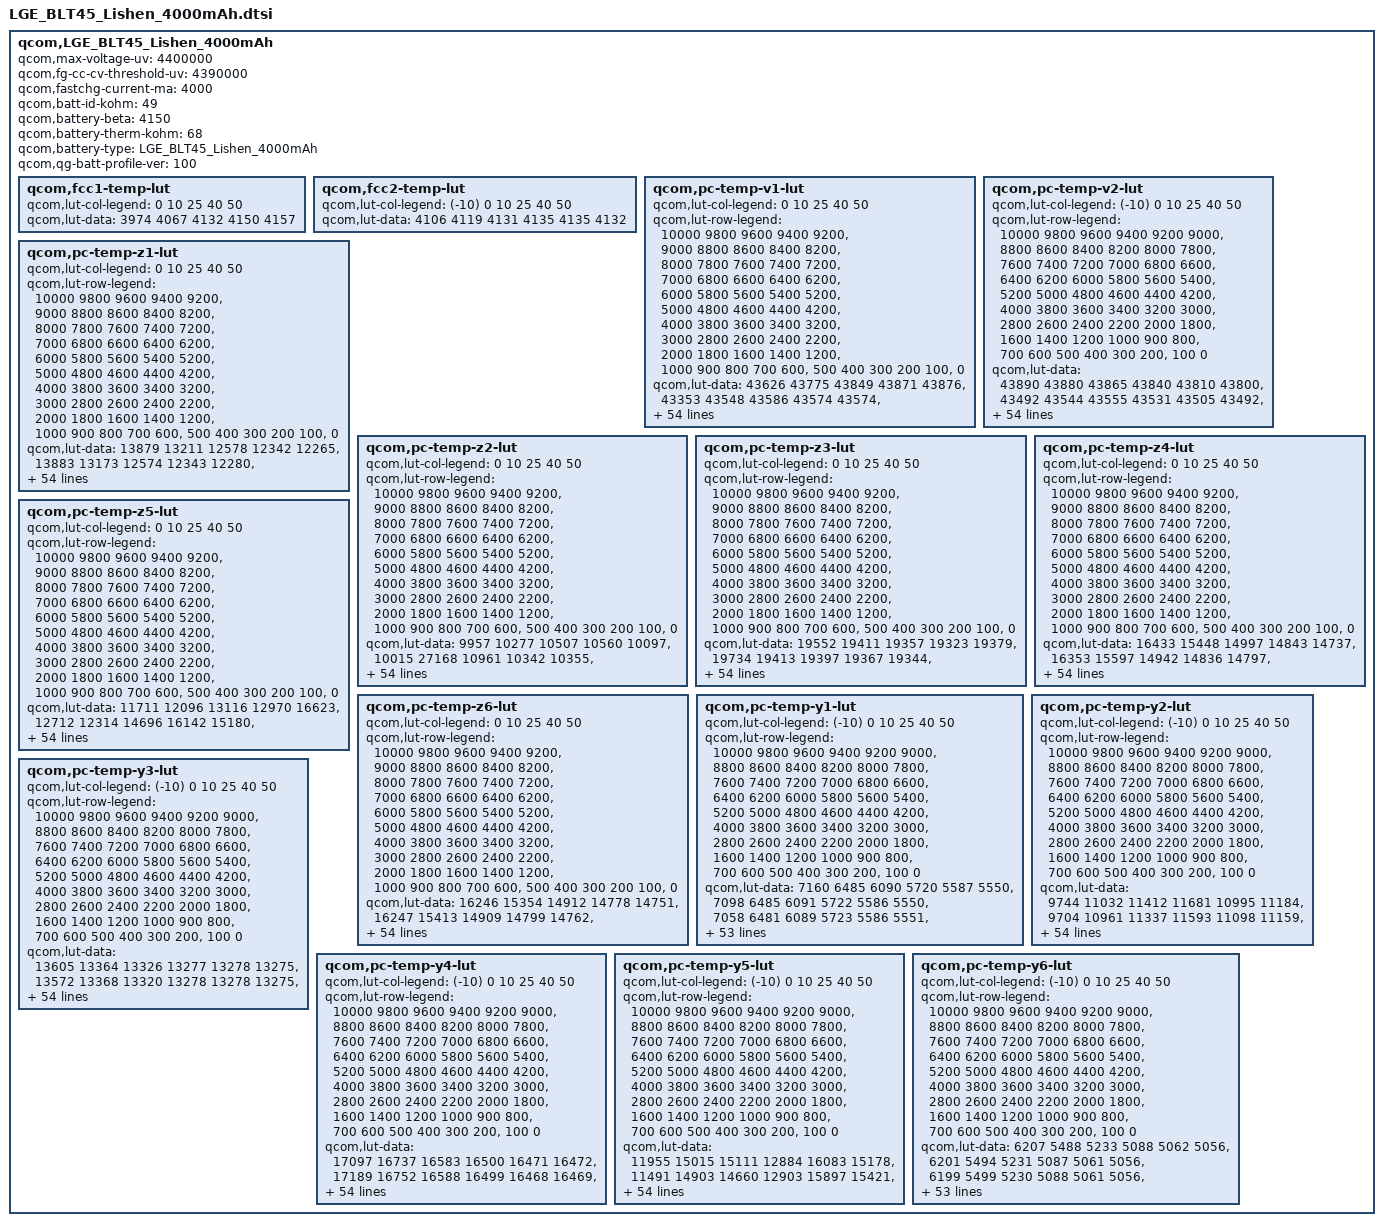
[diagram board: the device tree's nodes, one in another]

qcom,LGE_BLT45_Lishen_4000mAh {
    /* 3888979_LGE_BLT45_4000mAh_averaged_MasterSlave_Mar6th2019 */
    qcom,max-voltage-uv = <4400000>;
    qcom,fg-cc-cv-threshold-uv = <4390000>;
    qcom,fastchg-current-ma = <4000>;
    qcom,batt-id-kohm = <49>;
    qcom,battery-beta = <4150>;
    qcom,battery-therm-kohm = <68>;
    qcom,battery-type = "LGE_BLT45_Lishen_4000mAh";
    qcom,qg-batt-profile-ver = <100>;

	qcom,fcc1-temp-lut {
		qcom,lut-col-legend = <0 10 25 40 50>;
		qcom,lut-data = <3974 4067 4132 4150 4157>;
	};

	qcom,fcc2-temp-lut {
		qcom,lut-col-legend = <(-10) 0 10 25 40 50>;
		qcom,lut-data = <4106 4119 4131 4135 4135 4132>;
	};

	qcom,pc-temp-v1-lut {
		qcom,lut-col-legend = <0 10 25 40 50>;
		qcom,lut-row-legend = <10000 9800 9600 9400 9200>,
			<9000 8800 8600 8400 8200>,
			<8000 7800 7600 7400 7200>,
			<7000 6800 6600 6400 6200>,
			<6000 5800 5600 5400 5200>,
			<5000 4800 4600 4400 4200>,
			<4000 3800 3600 3400 3200>,
			<3000 2800 2600 2400 2200>,
			<2000 1800 1600 1400 1200>,
			<1000 900 800 700 600>,
			<500 400 300 200 100>,
			<0>;
		qcom,lut-data = <43626 43775 43849 43871 43876>,
			<43353 43548 43586 43574 43574>,
			<43091 43292 43343 43330 43326>,
			<42841 43026 43101 43094 43092>,
			<42601 42777 42859 42860 42861>,
			<42365 42536 42615 42623 42626>,
			<42134 42299 42372 42385 42390>,
			<41907 42064 42135 42151 42158>,
			<41684 41834 41903 41924 41930>,
			<41466 41609 41676 41698 41706>,
			<41255 41390 41453 41471 41481>,
			<41052 41182 41236 41248 41260>,
			<40854 40991 41024 41035 41044>,
			<40654 40801 40821 40832 40835>,
			<40453 40598 40622 40634 40633>,
			<40267 40393 40427 40441 40442>,
			<40097 40205 40242 40255 40259>,
			<39937 40034 40071 40080 40084>,
			<39784 39872 39911 39914 39916>,
			<39639 39725 39759 39756 39756>,
			<39497 39583 39621 39615 39613>,
			<39355 39418 39460 39460 39459>,
			<39216 39228 39211 39239 39245>,
			<39076 39037 38948 38992 39001>,
			<38935 38840 38798 38823 38829>,
			<38798 38662 38699 38705 38708>,
			<38652 38556 38606 38602 38602>,
			<38519 38487 38509 38504 38502>,
			<38427 38425 38419 38415 38410>,
			<38356 38364 38341 38332 38327>,
			<38304 38309 38271 38255 38252>,
			<38266 38257 38208 38187 38182>,
			<38236 38209 38152 38128 38117>,
			<38209 38166 38102 38074 38056>,
			<38186 38130 38063 38026 38001>,
			<38162 38097 38027 37980 37948>,
			<38138 38067 37990 37931 37890>,
			<38109 38040 37952 37878 37831>,
			<38064 37999 37904 37815 37761>,
			<37990 37920 37827 37736 37674>,
			<37899 37819 37728 37641 37572>,
			<37783 37708 37621 37535 37463>,
			<37649 37577 37497 37412 37340>,
			<37508 37420 37344 37264 37187>,
			<37349 37264 37193 37116 37042>,
			<37215 37147 37086 37017 36956>,
			<37170 37110 37055 36986 36927>,
			<37133 37083 37032 36963 36903>,
			<37102 37058 37010 36942 36884>,
			<37060 37022 36974 36899 36831>,
			<36911 36850 36785 36678 36587>,
			<36495 36435 36372 36256 36159>,
			<35923 35858 35803 35689 35592>,
			<35134 35059 35028 34915 34816>,
			<33861 33762 33827 33720 33617>,
			<30000 30000 30000 30000 30000>;
	};

	qcom,pc-temp-v2-lut {
		qcom,lut-col-legend = <(-10) 0 10 25 40 50>;
		qcom,lut-row-legend = <10000 9800 9600 9400 9200 9000>,
			<8800 8600 8400 8200 8000 7800>,
			<7600 7400 7200 7000 6800 6600>,
			<6400 6200 6000 5800 5600 5400>,
			<5200 5000 4800 4600 4400 4200>,
			<4000 3800 3600 3400 3200 3000>,
			<2800 2600 2400 2200 2000 1800>,
			<1600 1400 1200 1000 900 800>,
			<700 600 500 400 300 200>,
			<100 0>;
		qcom,lut-data = <43890 43880 43865 43840 43810 43800>,
			<43492 43544 43555 43531 43505 43492>,
			<43139 43236 43266 43243 43222 43207>,
			<42834 42961 43003 42981 42962 42948>,
			<42570 42715 42761 42741 42724 42712>,
			<42329 42474 42523 42504 42489 42479>,
			<42112 42232 42284 42265 42252 42244>,
			<41904 41995 42048 42029 42017 42010>,
			<41674 41765 41819 41798 41786 41780>,
			<41430 41542 41593 41571 41558 41553>,
			<41206 41323 41370 41347 41335 41330>,
			<41011 41110 41149 41127 41116 41111>,
			<40812 40900 40932 40912 40902 40897>,
			<40581 40697 40726 40706 40696 40692>,
			<40325 40496 40525 40506 40496 40491>,
			<40060 40282 40328 40312 40304 40300>,
			<39771 40054 40137 40122 40121 40116>,
			<39510 39830 39945 39944 39946 39941>,
			<39307 39616 39753 39786 39784 39778>,
			<39128 39410 39558 39630 39625 39619>,
			<38954 39216 39350 39441 39453 39448>,
			<38785 39029 39133 39224 39271 39271>,
			<38631 38862 38943 39020 39080 39084>,
			<38487 38715 38782 38827 38865 38870>,
			<38361 38580 38641 38658 38672 38676>,
			<38262 38452 38514 38531 38541 38544>,
			<38181 38332 38400 38425 38438 38439>,
			<38113 38226 38298 38328 38341 38341>,
			<38056 38133 38206 38238 38251 38250>,
			<38004 38051 38122 38158 38169 38166>,
			<37955 37982 38045 38087 38096 38090>,
			<37907 37923 37973 38021 38027 38019>,
			<37858 37873 37908 37960 37967 37958>,
			<37805 37833 37849 37902 37913 37904>,
			<37751 37792 37796 37844 37853 37841>,
			<37693 37745 37752 37786 37774 37749>,
			<37630 37695 37708 37724 37686 37646>,
			<37562 37639 37657 37651 37596 37545>,
			<37489 37575 37598 37569 37501 37443>,
			<37411 37503 37530 37490 37415 37352>,
			<37325 37416 37452 37418 37344 37279>,
			<37231 37316 37355 37331 37257 37192>,
			<37127 37202 37232 37220 37145 37080>,
			<37024 37064 37100 37099 37025 36961>,
			<36931 36926 36938 36950 36880 36819>,
			<36826 36819 36863 36889 36831 36776>,
			<36775 36778 36831 36873 36817 36760>,
			<36719 36738 36807 36852 36797 36747>,
			<36654 36688 36768 36830 36773 36719>,
			<36561 36611 36704 36779 36708 36638>,
			<36401 36443 36496 36594 36458 36343>,
			<36110 36038 35997 36128 35972 35853>,
			<35604 35423 35306 35510 35334 35205>,
			<34786 34552 34347 34646 34444 34303>,
			<33329 33070 32940 33367 33131 32954>,
			<30767 29268 27853 27944 27987 27971>;
	};

	qcom,pc-temp-z1-lut {
		qcom,lut-col-legend = <0 10 25 40 50>;
		qcom,lut-row-legend = <10000 9800 9600 9400 9200>,
			<9000 8800 8600 8400 8200>,
			<8000 7800 7600 7400 7200>,
			<7000 6800 6600 6400 6200>,
			<6000 5800 5600 5400 5200>,
			<5000 4800 4600 4400 4200>,
			<4000 3800 3600 3400 3200>,
			<3000 2800 2600 2400 2200>,
			<2000 1800 1600 1400 1200>,
			<1000 900 800 700 600>,
			<500 400 300 200 100>,
			<0>;
		qcom,lut-data = <13879 13211 12578 12342 12265>,
			<13883 13173 12574 12343 12280>,
			<13886 13166 12570 12336 12280>,
			<13888 13163 12564 12335 12281>,
			<13887 13164 12559 12334 12281>,
			<13882 13166 12555 12335 12283>,
			<13871 13166 12552 12336 12286>,
			<13859 13153 12552 12337 12288>,
			<13852 13137 12553 12337 12289>,
			<13845 13134 12553 12338 12290>,
			<13839 13132 12552 12338 12291>,
			<13828 13132 12551 12338 12291>,
			<13814 13136 12552 12338 12292>,
			<13803 13140 12552 12338 12293>,
			<13792 13136 12553 12339 12294>,
			<13789 13127 12552 12340 12295>,
			<13798 13126 12551 12341 12296>,
			<13808 13134 12552 12342 12297>,
			<13808 13140 12555 12344 12298>,
			<13806 13141 12559 12346 12300>,
			<13806 13141 12562 12347 12302>,
			<13818 13144 12566 12349 12304>,
			<13830 13153 12571 12351 12307>,
			<13833 13160 12576 12355 12310>,
			<13834 13165 12581 12360 12314>,
			<13836 13171 12587 12365 12318>,
			<13841 13176 12594 12369 12321>,
			<13847 13183 12600 12372 12324>,
			<13855 13189 12606 12376 12327>,
			<13867 13195 12610 12378 12330>,
			<13877 13200 12613 12381 12332>,
			<13884 13206 12617 12383 12334>,
			<13890 13216 12620 12387 12336>,
			<13896 13220 12623 12390 12338>,
			<13901 13215 12626 12393 12341>,
			<13906 13212 12629 12396 12344>,
			<13915 13217 12633 12399 12347>,
			<13925 13230 12637 12401 12350>,
			<13929 13237 12641 12404 12352>,
			<13930 13247 12645 12407 12355>,
			<13934 13255 12650 12411 12357>,
			<13955 13257 12654 12414 12360>,
			<13971 13260 12658 12416 12363>,
			<13952 13273 12662 12420 12366>,
			<13966 13277 12667 12423 12368>,
			<13959 13280 12678 12425 12369>,
			<13941 13273 12675 12426 12370>,
			<13969 13277 12674 12427 12371>,
			<13937 13272 12676 12428 12372>,
			<13943 13287 12684 12432 12376>,
			<13967 13298 12697 12439 12381>,
			<14000 13305 12703 12448 12391>,
			<13988 13333 12724 12463 12404>,
			<14030 13365 12752 12484 12422>,
			<14030 13365 12752 12484 12422>,
			<14030 13365 12752 12484 12422>;
	};

	qcom,pc-temp-z2-lut {
		qcom,lut-col-legend = <0 10 25 40 50>;
		qcom,lut-row-legend = <10000 9800 9600 9400 9200>,
			<9000 8800 8600 8400 8200>,
			<8000 7800 7600 7400 7200>,
			<7000 6800 6600 6400 6200>,
			<6000 5800 5600 5400 5200>,
			<5000 4800 4600 4400 4200>,
			<4000 3800 3600 3400 3200>,
			<3000 2800 2600 2400 2200>,
			<2000 1800 1600 1400 1200>,
			<1000 900 800 700 600>,
			<500 400 300 200 100>,
			<0>;
		qcom,lut-data = <9957 10277 10507 10560 10097>,
			<10015 27168 10961 10342 10355>,
			<10048 19545 11415 10492 10292>,
			<10050 10977 11205 10868 10307>,
			<10050 10253 10941 11244 10315>,
			<10050 10234 10696 11092 10344>,
			<10049 10218 10479 10616 10408>,
			<10047 10202 10484 10481 10424>,
			<10043 10192 10683 10767 10330>,
			<10035 10196 10799 11001 10246>,
			<10025 10215 10786 10829 10247>,
			<10012 10253 10767 10522 10254>,
			<10002 10384 10772 10509 10262>,
			<10000 10501 10786 10755 10275>,
			<10000 10535 10792 10915 10286>,
			<10004 10557 10784 10946 10291>,
			<10103 10550 10763 10962 10296>,
			<10213 10462 10696 10851 10312>,
			<10197 10397 10595 10520 10346>,
			<10120 10414 10574 10405 10371>,
			<10085 10449 10590 10418 10385>,
			<10104 10467 10601 10439 10397>,
			<10135 10478 10590 10501 10414>,
			<10163 10483 10575 10589 10432>,
			<10192 10482 10581 10612 10442>,
			<10218 10478 10611 10609 10443>,
			<10240 10471 10625 10599 10433>,
			<10259 10455 10602 10526 10379>,
			<10277 10447 10572 10442 10305>,
			<10294 10450 10555 10431 10265>,
			<10308 10456 10542 10429 10236>,
			<10319 10466 10541 10425 10228>,
			<10329 10487 10556 10392 10249>,
			<10343 10509 10579 10363 10282>,
			<10361 10530 10606 10374 10315>,
			<10381 10552 10638 10406 10354>,
			<10407 10573 10661 10446 10403>,
			<10435 10592 10677 10511 10471>,
			<10462 10611 10697 10572 10521>,
			<10489 10630 10735 10631 10546>,
			<10513 10647 10775 10678 10562>,
			<10540 10656 10791 10681 10561>,
			<10553 10664 10800 10668 10550>,
			<10198 10684 10807 10656 10548>,
			<13003 10791 10834 10649 10543>,
			<13477 10961 10885 10685 10524>,
			<15126 11039 10899 10689 10537>,
			<19313 11519 10911 10688 10547>,
			<15753 12078 10894 10702 10644>,
			<19263 12169 10929 10870 10698>,
			<16093 11828 11098 10668 10446>,
			<16101 11528 11055 10502 10289>,
			<10893 11351 10911 10437 10220>,
			<10142 10879 10911 10351 10124>,
			<10142 10879 10911 10351 10124>,
			<10142 10879 10911 10351 10124>;
	};

	qcom,pc-temp-z3-lut {
		qcom,lut-col-legend = <0 10 25 40 50>;
		qcom,lut-row-legend = <10000 9800 9600 9400 9200>,
			<9000 8800 8600 8400 8200>,
			<8000 7800 7600 7400 7200>,
			<7000 6800 6600 6400 6200>,
			<6000 5800 5600 5400 5200>,
			<5000 4800 4600 4400 4200>,
			<4000 3800 3600 3400 3200>,
			<3000 2800 2600 2400 2200>,
			<2000 1800 1600 1400 1200>,
			<1000 900 800 700 600>,
			<500 400 300 200 100>,
			<0>;
		qcom,lut-data = <19552 19411 19357 19323 19379>,
			<19734 19413 19397 19367 19344>,
			<19841 19509 19427 19394 19375>,
			<19850 19619 19451 19409 19382>,
			<19853 19631 19467 19417 19386>,
			<19853 19632 19466 19418 19392>,
			<19838 19633 19465 19415 19399>,
			<19819 19631 19466 19414 19401>,
			<19808 19627 19473 19413 19391>,
			<19799 19614 19475 19411 19380>,
			<19791 19589 19464 19405 19378>,
			<19784 19583 19453 19394 19377>,
			<19778 19610 19451 19391 19375>,
			<19766 19633 19451 19389 19374>,
			<19748 19621 19450 19387 19372>,
			<19741 19591 19440 19385 19367>,
			<19756 19567 19427 19382 19361>,
			<19773 19545 19418 19378 19358>,
			<19754 19531 19409 19370 19357>,
			<19693 19524 19405 19365 19354>,
			<19666 19520 19402 19361 19350>,
			<19675 19523 19401 19359 19347>,
			<19688 19549 19415 19361 19348>,
			<19700 19568 19434 19365 19353>,
			<19711 19572 19433 19375 19361>,
			<19721 19574 19419 19396 19383>,
			<19729 19573 19413 19408 19395>,
			<19734 19566 19426 19406 19394>,
			<19733 19559 19440 19403 19391>,
			<19726 19553 19440 19400 19386>,
			<19718 19548 19436 19398 19378>,
			<19709 19548 19434 19394 19371>,
			<19698 19547 19432 19385 19367>,
			<19687 19547 19430 19376 19363>,
			<19676 19544 19426 19370 19358>,
			<19666 19540 19422 19364 19352>,
			<19657 19535 19418 19363 19348>,
			<19649 19529 19415 19362 19344>,
			<19641 19524 19413 19362 19343>,
			<19634 19520 19412 19362 19346>,
			<19625 19516 19410 19361 19352>,
			<19613 19510 19408 19359 19352>,
			<19591 19503 19404 19356 19350>,
			<19339 19494 19401 19356 19356>,
			<19258 19468 19395 19357 19362>,
			<19257 19438 19384 19347 19346>,
			<19257 19423 19377 19342 19339>,
			<19256 19333 19366 19340 19335>,
			<19257 19288 19366 19337 19321>,
			<19256 19280 19361 19321 19320>,
			<19257 19311 19350 19348 19349>,
			<19257 19309 19348 19358 19356>,
			<19259 19308 19363 19359 19358>,
			<19261 19328 19349 19363 19362>,
			<19261 19328 19349 19363 19362>,
			<19261 19328 19349 19363 19362>;
	};

	qcom,pc-temp-z4-lut {
		qcom,lut-col-legend = <0 10 25 40 50>;
		qcom,lut-row-legend = <10000 9800 9600 9400 9200>,
			<9000 8800 8600 8400 8200>,
			<8000 7800 7600 7400 7200>,
			<7000 6800 6600 6400 6200>,
			<6000 5800 5600 5400 5200>,
			<5000 4800 4600 4400 4200>,
			<4000 3800 3600 3400 3200>,
			<3000 2800 2600 2400 2200>,
			<2000 1800 1600 1400 1200>,
			<1000 900 800 700 600>,
			<500 400 300 200 100>,
			<0>;
		qcom,lut-data = <16433 15448 14997 14843 14737>,
			<16353 15597 14942 14836 14797>,
			<16232 15478 15015 14884 14848>,
			<16052 15298 14945 14849 14835>,
			<15810 15181 14874 14804 14811>,
			<15624 15085 14844 14786 14787>,
			<15494 15011 14821 14772 14762>,
			<15388 14954 14792 14760 14750>,
			<15301 14910 14750 14736 14746>,
			<15227 14882 14727 14718 14742>,
			<15164 14861 14725 14719 14736>,
			<15107 14829 14723 14724 14730>,
			<15059 14760 14716 14722 14723>,
			<15026 14710 14703 14707 14717>,
			<15001 14720 14699 14696 14711>,
			<14966 14745 14702 14690 14706>,
			<14892 14761 14706 14685 14701>,
			<14830 14772 14709 14684 14696>,
			<14839 14777 14711 14688 14689>,
			<14880 14771 14709 14688 14684>,
			<14898 14762 14705 14684 14680>,
			<14875 14761 14702 14682 14677>,
			<14848 14775 14766 14732 14721>,
			<14843 14796 14856 14825 14809>,
			<14841 14842 14864 14836 14824>,
			<14840 14893 14845 14794 14782>,
			<14868 14895 14821 14758 14746>,
			<14902 14868 14788 14741 14732>,
			<14907 14843 14757 14728 14722>,
			<14908 14825 14742 14717 14715>,
			<14907 14810 14732 14708 14709>,
			<14897 14796 14725 14702 14703>,
			<14880 14784 14719 14699 14695>,
			<14866 14775 14715 14696 14689>,
			<14853 14770 14711 14693 14686>,
			<14839 14766 14708 14691 14684>,
			<14823 14759 14707 14691 14684>,
			<14808 14752 14706 14694 14689>,
			<14795 14748 14706 14697 14695>,
			<14783 14746 14711 14704 14700>,
			<14775 14744 14717 14711 14704>,
			<14772 14736 14713 14709 14702>,
			<14771 14722 14701 14702 14696>,
			<15007 14715 14699 14704 14697>,
			<15030 14704 14694 14702 14695>,
			<14981 14690 14673 14685 14677>,
			<14975 14698 14670 14681 14674>,
			<14971 14794 14667 14666 14660>,
			<14961 14837 14654 14647 14650>,
			<14957 14838 14655 14654 14641>,
			<14956 14810 14684 14660 14655>,
			<14978 14824 14695 14661 14661>,
			<14994 14834 14681 14664 14662>,
			<15027 14831 14702 14662 14660>,
			<15027 14831 14702 14662 14660>,
			<15027 14831 14702 14662 14660>;
	};

	qcom,pc-temp-z5-lut {
		qcom,lut-col-legend = <0 10 25 40 50>;
		qcom,lut-row-legend = <10000 9800 9600 9400 9200>,
			<9000 8800 8600 8400 8200>,
			<8000 7800 7600 7400 7200>,
			<7000 6800 6600 6400 6200>,
			<6000 5800 5600 5400 5200>,
			<5000 4800 4600 4400 4200>,
			<4000 3800 3600 3400 3200>,
			<3000 2800 2600 2400 2200>,
			<2000 1800 1600 1400 1200>,
			<1000 900 800 700 600>,
			<500 400 300 200 100>,
			<0>;
		qcom,lut-data = <11711 12096 13116 12970 16623>,
			<12712 12314 14696 16142 15180>,
			<13418 13544 15534 17498 17535>,
			<13758 15208 16473 18666 18276>,
			<13977 15909 17447 19535 18815>,
			<14160 16337 18048 20157 20007>,
			<14312 16819 18615 20633 21808>,
			<14458 17550 19823 21006 22336>,
			<14632 18075 22310 21827 21219>,
			<14829 18098 23535 22421 20226>,
			<15052 18077 22788 22076 20390>,
			<15369 18204 21896 21425 20878>,
			<15659 19728 22328 21313 21407>,
			<15802 21169 23839 21612 22136>,
			<15958 21274 24297 22184 22495>,
			<16276 21057 22748 22898 22161>,
			<18075 20737 21105 23455 21722>,
			<19912 20173 20574 23330 21969>,
			<19496 19818 20327 22562 22967>,
			<17730 20071 20439 22423 23539>,
			<16971 20833 20694 22674 23746>,
			<18385 23407 21134 22815 23844>,
			<20892 32414 24251 21852 22367>,
			<23706 37886 28261 20075 19354>,
			<27352 36562 27146 19725 18698>,
			<30815 33939 20920 19858 19144>,
			<34518 31284 18099 20066 19755>,
			<37272 28099 19517 20590 20809>,
			<37227 26435 21465 21445 21842>,
			<35797 26045 22527 22688 21909>,
			<34198 25842 23342 24418 21732>,
			<32556 26367 24453 24962 21701>,
			<30933 28403 26191 24319 22611>,
			<29685 30238 27742 23737 23716>,
			<28567 31830 28727 23950 24280>,
			<28093 32886 29464 24567 24688>,
			<28184 32830 29796 25295 24665>,
			<28389 32505 30003 26355 23966>,
			<28639 32361 30076 26907 23503>,
			<29086 32364 29776 26007 23745>,
			<29312 32360 29242 24392 24087>,
			<27828 31918 28742 23074 23737>,
			<24508 30764 28167 21928 22630>,
			<14110 28965 27373 21634 24201>,
			<11541 26042 26731 21790 26014>,
			<11647 23231 26442 20450 21917>,
			<11639 20371 24201 19401 19344>,
			<11618 13515 21497 19971 19875>,
			<11577 12107 22234 22393 18924>,
			<11580 11961 21443 18378 19961>,
			<11598 12749 17526 21035 23141>,
			<11563 12555 16291 20794 21800>,
			<11493 12422 17954 19516 19998>,
			<11398 12758 15562 19045 19304>,
			<11398 12758 15562 19045 19304>,
			<11398 12758 15562 19045 19304>;
	};

	qcom,pc-temp-z6-lut {
		qcom,lut-col-legend = <0 10 25 40 50>;
		qcom,lut-row-legend = <10000 9800 9600 9400 9200>,
			<9000 8800 8600 8400 8200>,
			<8000 7800 7600 7400 7200>,
			<7000 6800 6600 6400 6200>,
			<6000 5800 5600 5400 5200>,
			<5000 4800 4600 4400 4200>,
			<4000 3800 3600 3400 3200>,
			<3000 2800 2600 2400 2200>,
			<2000 1800 1600 1400 1200>,
			<1000 900 800 700 600>,
			<500 400 300 200 100>,
			<0>;
		qcom,lut-data = <16246 15354 14912 14778 14751>,
			<16247 15413 14909 14799 14762>,
			<16246 15393 14953 14832 14799>,
			<16196 15361 14933 14825 14796>,
			<16060 15326 14911 14814 14790>,
			<15949 15273 14897 14806 14785>,
			<15870 15229 14885 14799 14780>,
			<15804 15199 14872 14792 14774>,
			<15750 15173 14859 14782 14767>,
			<15705 15148 14848 14774 14760>,
			<15666 15125 14841 14770 14756>,
			<15631 15106 14835 14766 14752>,
			<15600 15089 14830 14762 14749>,
			<15571 15077 14825 14755 14745>,
			<15545 15072 14821 14750 14741>,
			<15523 15069 14817 14746 14736>,
			<15505 15064 14813 14743 14732>,
			<15490 15058 14809 14740 14727>,
			<15478 15052 14805 14737 14724>,
			<15469 15047 14802 14734 14720>,
			<15465 15042 14800 14730 14717>,
			<15463 15044 14799 14729 14714>,
			<15462 15063 14835 14753 14735>,
			<15464 15086 14885 14797 14776>,
			<15472 15113 14889 14805 14786>,
			<15483 15137 14875 14800 14781>,
			<15504 15137 14864 14793 14775>,
			<15523 15125 14858 14786 14769>,
			<15525 15113 14853 14779 14763>,
			<15524 15105 14847 14773 14757>,
			<15522 15098 14841 14768 14751>,
			<15516 15093 14837 14763 14745>,
			<15507 15089 14834 14757 14740>,
			<15499 15086 14831 14751 14735>,
			<15491 15083 14828 14747 14730>,
			<15485 15081 14825 14743 14725>,
			<15479 15078 14823 14742 14724>,
			<15474 15074 14822 14743 14725>,
			<15471 15073 14822 14744 14725>,
			<15469 15074 14824 14747 14729>,
			<15467 15075 14827 14750 14734>,
			<15465 15072 14825 14749 14734>,
			<15462 15066 14818 14745 14730>,
			<15450 15063 14817 14746 14734>,
			<15423 15052 14814 14746 14737>,
			<15411 15036 14801 14734 14721>,
			<15412 15034 14796 14729 14716>,
			<15412 15032 14790 14722 14709>,
			<15411 15031 14785 14713 14697>,
			<15416 15033 14784 14708 14692>,
			<15429 15045 14793 14725 14714>,
			<15454 15061 14801 14734 14724>,
			<15484 15078 14808 14738 14728>,
			<15533 15109 14818 14744 14734>,
			<15533 15109 14818 14744 14734>,
			<15533 15109 14818 14744 14734>;
	};

	qcom,pc-temp-y1-lut {
		qcom,lut-col-legend = <(-10) 0 10 25 40 50>;
		qcom,lut-row-legend = <10000 9800 9600 9400 9200 9000>,
			<8800 8600 8400 8200 8000 7800>,
			<7600 7400 7200 7000 6800 6600>,
			<6400 6200 6000 5800 5600 5400>,
			<5200 5000 4800 4600 4400 4200>,
			<4000 3800 3600 3400 3200 3000>,
			<2800 2600 2400 2200 2000 1800>,
			<1600 1400 1200 1000 900 800>,
			<700 600 500 400 300 200>,
			<100 0>;
		qcom,lut-data = <7160 6485 6090 5720 5587 5550>,
			<7098 6485 6091 5722 5586 5550>,
			<7058 6481 6089 5723 5586 5551>,
			<7035 6477 6087 5723 5585 5551>,
			<7025 6472 6085 5723 5584 5551>,
			<7024 6469 6083 5722 5584 5551>,
			<7044 6467 6082 5719 5584 5552>,
			<7067 6464 6080 5715 5584 5552>,
			<7065 6465 6078 5715 5584 5552>,
			<7050 6468 6076 5716 5585 5551>,
			<7039 6470 6075 5716 5584 5551>,
			<7030 6467 6075 5715 5583 5552>,
			<7025 6466 6076 5714 5582 5552>,
			<7029 6467 6076 5715 5582 5552>,
			<7040 6468 6077 5715 5583 5553>,
			<7046 6468 6078 5716 5584 5553>,
			<7050 6469 6078 5717 5587 5555>,
			<7052 6470 6078 5718 5588 5557>,
			<7051 6471 6076 5719 5589 5558>,
			<7047 6474 6074 5720 5589 5559>,
			<7047 6478 6074 5721 5590 5560>,
			<7060 6484 6076 5723 5591 5560>,
			<7066 6486 6078 5725 5592 5560>,
			<7053 6483 6080 5728 5594 5561>,
			<7036 6479 6081 5731 5595 5563>,
			<7039 6480 6084 5732 5596 5565>,
			<7056 6486 6088 5733 5598 5567>,
			<7064 6488 6090 5734 5599 5568>,
			<7073 6491 6091 5738 5601 5569>,
			<7082 6494 6093 5742 5603 5570>,
			<7074 6497 6096 5746 5605 5571>,
			<7054 6502 6099 5751 5607 5573>,
			<7047 6502 6100 5753 5609 5575>,
			<7047 6493 6101 5755 5612 5578>,
			<7046 6488 6101 5757 5614 5580>,
			<7041 6492 6102 5761 5616 5581>,
			<7033 6499 6104 5764 5618 5582>,
			<7032 6500 6105 5766 5620 5583>,
			<7035 6499 6105 5767 5621 5585>,
			<7037 6499 6105 5768 5622 5586>,
			<7036 6508 6105 5769 5625 5588>,
			<7036 6514 6106 5770 5626 5590>,
			<7038 6515 6115 5772 5627 5591>,
			<7041 6520 6113 5778 5628 5593>,
			<7051 6514 6121 5779 5631 5595>,
			<7074 6515 6130 5782 5633 5597>,
			<7072 6518 6125 5782 5635 5597>,
			<7068 6533 6123 5782 5634 5598>,
			<7085 6511 6130 5786 5635 5599>,
			<7083 6519 6126 5788 5636 5601>,
			<7113 6524 6134 5791 5638 5603>,
			<7118 6526 6143 5801 5644 5611>,
			<7159 6566 6161 5813 5657 5618>,
			<7298 6653 6197 5831 5670 5632>,
			<7298 6653 6197 5831 5670 5632>,
			<7298 6653 6197 5831 5670 5632>;
	};

	qcom,pc-temp-y2-lut {
		qcom,lut-col-legend = <(-10) 0 10 25 40 50>;
		qcom,lut-row-legend = <10000 9800 9600 9400 9200 9000>,
			<8800 8600 8400 8200 8000 7800>,
			<7600 7400 7200 7000 6800 6600>,
			<6400 6200 6000 5800 5600 5400>,
			<5200 5000 4800 4600 4400 4200>,
			<4000 3800 3600 3400 3200 3000>,
			<2800 2600 2400 2200 2000 1800>,
			<1600 1400 1200 1000 900 800>,
			<700 600 500 400 300 200>,
			<100 0>;
		qcom,lut-data = <9744 11032 11412 11681 10995 11184>,
			<9704 10961 11337 11593 11098 11159>,
			<9685 10891 11264 11504 11156 11134>,
			<9686 10827 11197 11420 11180 11109>,
			<9704 10771 11137 11351 11182 11084>,
			<9742 10731 11088 11302 11170 11058>,
			<10055 10696 11050 11273 11116 11027>,
			<10418 10675 11014 11246 11063 11002>,
			<10481 10674 10970 11198 11061 10992>,
			<10497 10677 10924 11133 11066 10986>,
			<10529 10681 10899 11096 11065 10982>,
			<10620 10696 10884 11076 11039 10967>,
			<10692 10721 10877 11064 11018 10953>,
			<10690 10769 10879 11068 11021 10948>,
			<10674 10832 10886 11084 11026 10942>,
			<10585 10848 10904 11087 11021 10933>,
			<10079 10844 10958 11085 10986 10917>,
			<9709 10843 11005 11088 10967 10907>,
			<9699 10880 11024 11122 10992 10907>,
			<9694 10944 11040 11161 11037 10913>,
			<9688 10993 11078 11168 11084 10949>,
			<9683 11036 11145 11170 11143 11050>,
			<9679 11073 11207 11182 11173 11100>,
			<9678 11104 11253 11336 11181 11124>,
			<9678 11128 11303 11486 11189 11154>,
			<9676 11102 11392 11494 11224 11188>,
			<9674 10999 11500 11483 11282 11233>,
			<9672 10984 11528 11494 11311 11251>,
			<9670 11186 11528 11548 11325 11250>,
			<9668 11358 11529 11584 11339 11253>,
			<9665 11219 11543 11561 11368 11305>,
			<9663 10873 11567 11519 11398 11376>,
			<9661 10555 11571 11494 11399 11386>,
			<9660 10206 11561 11475 11385 11373>,
			<9659 10033 11548 11466 11379 11361>,
			<9658 10159 11524 11470 11402 11340>,
			<9657 10339 11498 11482 11428 11319>,
			<9656 10285 11476 11511 11420 11308>,
			<9656 9963 11446 11571 11391 11295>,
			<9655 9766 11423 11589 11380 11288>,
			<9655 9719 11343 11562 11402 11258>,
			<9655 9697 11279 11545 11411 11244>,
			<9655 9687 11231 11545 11400 11216>,
			<9654 9680 11185 11551 11377 11217>,
			<9654 9676 10977 11560 11417 11235>,
			<9654 9668 10591 11591 11359 11168>,
			<9654 9665 10696 11590 11292 11086>,
			<9654 9662 10494 11557 11246 10991>,
			<9654 9660 10399 11435 11146 10974>,
			<9653 9658 10732 11389 11127 10931>,
			<9653 9656 10591 11400 11105 10950>,
			<9652 9654 10046 11508 11067 10848>,
			<9649 9652 9743 11286 10987 10785>,
			<9648 9649 9663 11130 10795 10628>,
			<9648 9649 9663 11130 10795 10628>,
			<9648 9649 9663 11130 10795 10628>;
	};

	qcom,pc-temp-y3-lut {
		qcom,lut-col-legend = <(-10) 0 10 25 40 50>;
		qcom,lut-row-legend = <10000 9800 9600 9400 9200 9000>,
			<8800 8600 8400 8200 8000 7800>,
			<7600 7400 7200 7000 6800 6600>,
			<6400 6200 6000 5800 5600 5400>,
			<5200 5000 4800 4600 4400 4200>,
			<4000 3800 3600 3400 3200 3000>,
			<2800 2600 2400 2200 2000 1800>,
			<1600 1400 1200 1000 900 800>,
			<700 600 500 400 300 200>,
			<100 0>;
		qcom,lut-data = <13605 13364 13326 13277 13278 13275>,
			<13572 13368 13320 13278 13278 13275>,
			<13548 13372 13315 13279 13279 13276>,
			<13534 13377 13312 13280 13279 13277>,
			<13526 13381 13310 13281 13279 13278>,
			<13524 13385 13309 13281 13279 13278>,
			<13535 13388 13311 13282 13279 13279>,
			<13547 13392 13313 13282 13280 13279>,
			<13548 13396 13317 13284 13280 13280>,
			<13547 13401 13325 13290 13280 13280>,
			<13544 13403 13329 13292 13280 13280>,
			<13529 13404 13330 13291 13280 13280>,
			<13510 13404 13332 13291 13280 13279>,
			<13499 13404 13335 13291 13280 13279>,
			<13488 13402 13338 13292 13281 13279>,
			<13476 13399 13341 13294 13281 13280>,
			<13458 13391 13343 13298 13285 13281>,
			<13444 13383 13343 13301 13288 13282>,
			<13437 13375 13341 13305 13290 13283>,
			<13430 13368 13337 13307 13292 13285>,
			<13419 13362 13332 13306 13292 13287>,
			<13399 13355 13326 13302 13292 13288>,
			<13383 13351 13321 13297 13291 13288>,
			<13370 13348 13317 13289 13285 13283>,
			<13362 13346 13313 13283 13279 13277>,
			<13363 13338 13306 13282 13279 13277>,
			<13374 13322 13298 13281 13279 13277>,
			<13388 13309 13296 13281 13279 13276>,
			<13406 13299 13298 13281 13279 13276>,
			<13430 13293 13299 13281 13278 13276>,
			<13462 13282 13299 13284 13278 13276>,
			<13505 13264 13299 13289 13278 13275>,
			<13555 13259 13299 13290 13278 13275>,
			<13614 13261 13298 13289 13279 13276>,
			<13682 13263 13298 13289 13280 13276>,
			<13757 13277 13300 13289 13279 13276>,
			<13842 13299 13302 13289 13278 13276>,
			<13939 13314 13303 13287 13277 13275>,
			<14052 13327 13304 13283 13277 13275>,
			<14172 13331 13304 13282 13277 13276>,
			<14299 13324 13308 13285 13279 13277>,
			<14433 13321 13310 13286 13279 13277>,
			<14575 13347 13311 13285 13279 13277>,
			<14741 13362 13310 13283 13278 13278>,
			<14757 13379 13286 13284 13277 13276>,
			<14983 13446 13301 13283 13278 13279>,
			<15125 13493 13300 13285 13281 13280>,
			<15284 13562 13311 13282 13282 13285>,
			<15466 13657 13318 13293 13288 13287>,
			<15691 13797 13340 13297 13290 13287>,
			<16003 14010 13349 13294 13286 13282>,
			<16722 14434 13349 13284 13284 13284>,
			<21100 15565 13407 13294 13286 13285>,
			<46238 21049 13786 13297 13290 13290>,
			<46238 21049 13786 13297 13290 13290>,
			<46238 21049 13786 13297 13290 13290>;
	};

	qcom,pc-temp-y4-lut {
		qcom,lut-col-legend = <(-10) 0 10 25 40 50>;
		qcom,lut-row-legend = <10000 9800 9600 9400 9200 9000>,
			<8800 8600 8400 8200 8000 7800>,
			<7600 7400 7200 7000 6800 6600>,
			<6400 6200 6000 5800 5600 5400>,
			<5200 5000 4800 4600 4400 4200>,
			<4000 3800 3600 3400 3200 3000>,
			<2800 2600 2400 2200 2000 1800>,
			<1600 1400 1200 1000 900 800>,
			<700 600 500 400 300 200>,
			<100 0>;
		qcom,lut-data = <17097 16737 16583 16500 16471 16472>,
			<17189 16752 16588 16499 16468 16469>,
			<17300 16774 16595 16499 16467 16466>,
			<17406 16796 16603 16499 16466 16464>,
			<17483 16814 16609 16499 16466 16462>,
			<17508 16822 16612 16499 16466 16462>,
			<17489 16825 16614 16502 16468 16463>,
			<17466 16827 16616 16506 16470 16464>,
			<17460 16834 16616 16504 16472 16465>,
			<17458 16850 16616 16501 16475 16466>,
			<17463 16869 16618 16501 16479 16468>,
			<17549 16892 16629 16509 16482 16472>,
			<17630 16921 16647 16519 16487 16476>,
			<17590 16969 16667 16528 16492 16480>,
			<17478 17023 16694 16537 16498 16484>,
			<17373 17031 16728 16547 16503 16489>,
			<17267 16999 16773 16558 16508 16493>,
			<17183 16956 16795 16574 16514 16499>,
			<17136 16902 16790 16615 16528 16509>,
			<17100 16839 16778 16656 16548 16521>,
			<17058 16786 16742 16653 16570 16538>,
			<17013 16737 16655 16624 16596 16561>,
			<16969 16700 16597 16588 16601 16567>,
			<16925 16671 16567 16533 16536 16519>,
			<16888 16651 16551 16493 16473 16471>,
			<16870 16647 16551 16488 16468 16467>,
			<16858 16653 16554 16487 16466 16466>,
			<16854 16657 16554 16487 16466 16466>,
			<16857 16659 16549 16489 16469 16468>,
			<16861 16660 16545 16492 16474 16472>,
			<16864 16677 16544 16493 16480 16477>,
			<16868 16710 16543 16496 16488 16485>,
			<16872 16722 16541 16500 16498 16495>,
			<16877 16729 16537 16510 16511 16508>,
			<16883 16732 16535 16514 16516 16513>,
			<16890 16719 16534 16510 16505 16500>,
			<16897 16699 16534 16503 16490 16482>,
			<16904 16701 16536 16493 16479 16475>,
			<16911 16720 16540 16478 16470 16469>,
			<16915 16742 16541 16473 16469 16469>,
			<16916 16765 16545 16473 16475 16477>,
			<16917 16774 16548 16473 16477 16479>,
			<16928 16769 16552 16475 16472 16474>,
			<16939 16765 16564 16482 16479 16481>,
			<16914 16750 16581 16460 16451 16447>,
			<16942 16753 16585 16466 16459 16457>,
			<16964 16766 16600 16475 16470 16475>,
			<17002 16788 16627 16495 16492 16507>,
			<17051 16826 16662 16509 16529 16547>,
			<17116 16892 16689 16546 16555 16563>,
			<17162 16982 16724 16537 16494 16482>,
			<17167 16982 16740 16495 16473 16472>,
			<17673 17073 16805 16495 16478 16478>,
			<28786 18382 17007 16526 16501 16501>,
			<28786 18382 17007 16526 16501 16501>,
			<28786 18382 17007 16526 16501 16501>;
	};

	qcom,pc-temp-y5-lut {
		qcom,lut-col-legend = <(-10) 0 10 25 40 50>;
		qcom,lut-row-legend = <10000 9800 9600 9400 9200 9000>,
			<8800 8600 8400 8200 8000 7800>,
			<7600 7400 7200 7000 6800 6600>,
			<6400 6200 6000 5800 5600 5400>,
			<5200 5000 4800 4600 4400 4200>,
			<4000 3800 3600 3400 3200 3000>,
			<2800 2600 2400 2200 2000 1800>,
			<1600 1400 1200 1000 900 800>,
			<700 600 500 400 300 200>,
			<100 0>;
		qcom,lut-data = <11955 15015 15111 12884 16083 15178>,
			<11491 14903 14660 12903 15897 15421>,
			<11292 14736 14086 12915 15697 15751>,
			<11301 14555 13509 12921 15492 16081>,
			<11462 14400 13045 12922 15290 16326>,
			<11732 14308 12811 12918 15096 16402>,
			<12694 14191 12698 12794 14895 16326>,
			<13686 14067 12652 12659 14707 16200>,
			<13800 14014 12856 13009 14495 16078>,
			<13816 13982 13327 13938 14188 15904>,
			<13852 13931 13461 14203 13983 15625>,
			<14009 13822 13252 13800 13783 14975>,
			<14272 13743 13080 13372 13588 14368>,
			<14859 13900 13093 13159 13397 14066>,
			<15699 14318 13143 13007 13228 13848>,
			<15675 14780 13287 13043 13299 13781>,
			<13820 15415 13822 13408 13851 13957>,
			<12404 15880 14487 13804 14275 14075>,
			<12340 16093 15322 14068 14382 14076>,
			<12321 16224 16147 14374 14480 14172>,
			<12224 16228 16580 15190 15056 14678>,
			<11961 16183 16881 16714 16448 15797>,
			<11678 16166 16959 17202 16964 16439>,
			<11390 16328 16705 15678 16519 16703>,
			<11139 16509 16240 14222 16097 16843>,
			<11019 15878 15252 14163 16388 16826>,
			<10942 14073 13788 14170 17055 16743>,
			<10905 13249 13450 14178 17151 16578>,
			<10885 13041 13872 14233 16526 16255>,
			<10875 12947 14245 14353 16018 15851>,
			<10922 12350 14326 15678 15882 15260>,
			<11056 11204 14365 17654 15789 14679>,
			<11174 10966 14420 18159 15898 14678>,
			<11281 11096 14502 18301 16399 15137>,
			<11360 11283 14612 18463 16742 15661>,
			<11397 11640 14950 19042 16869 16248>,
			<11413 12011 15308 19594 16951 16746>,
			<11421 12070 15518 18728 16995 16942>,
			<11457 12073 15891 16313 17007 17088>,
			<11479 12061 16016 15617 17044 17121>,
			<11477 11865 16312 16800 17425 17009>,
			<11467 11759 16421 17240 17562 16893>,
			<11192 11800 15980 17027 17368 16880>,
			<11091 11498 15331 15808 16360 17084>,
			<11207 11283 12027 17038 17921 18896>,
			<11173 11437 13403 16102 16064 17089>,
			<11292 11416 12999 16198 16241 16018>,
			<11358 11551 13892 14357 15390 16505>,
			<11499 11638 14095 17105 15925 15544>,
			<11563 11668 15282 17291 15604 14688>,
			<11642 11639 15052 16295 15554 14890>,
			<11575 11438 13472 14536 15689 16088>,
			<10453 11226 12177 17445 15853 15470>,
			<9134 9781 11626 17341 16697 16979>,
			<9134 9781 11626 17341 16697 16979>,
			<9134 9781 11626 17341 16697 16979>;
	};

	qcom,pc-temp-y6-lut {
		qcom,lut-col-legend = <(-10) 0 10 25 40 50>;
		qcom,lut-row-legend = <10000 9800 9600 9400 9200 9000>,
			<8800 8600 8400 8200 8000 7800>,
			<7600 7400 7200 7000 6800 6600>,
			<6400 6200 6000 5800 5600 5400>,
			<5200 5000 4800 4600 4400 4200>,
			<4000 3800 3600 3400 3200 3000>,
			<2800 2600 2400 2200 2000 1800>,
			<1600 1400 1200 1000 900 800>,
			<700 600 500 400 300 200>,
			<100 0>;
		qcom,lut-data = <6207 5488 5233 5088 5062 5056>,
			<6201 5494 5231 5087 5061 5056>,
			<6199 5499 5230 5088 5061 5056>,
			<6201 5503 5228 5088 5061 5056>,
			<6205 5505 5227 5088 5062 5057>,
			<6211 5506 5226 5089 5062 5057>,
			<6223 5504 5226 5090 5063 5058>,
			<6234 5503 5226 5091 5063 5058>,
			<6230 5504 5227 5093 5064 5059>,
			<6217 5508 5231 5095 5065 5060>,
			<6212 5512 5234 5097 5066 5061>,
			<6218 5516 5237 5099 5068 5061>,
			<6224 5521 5240 5101 5069 5062>,
			<6211 5531 5247 5104 5071 5064>,
			<6174 5542 5256 5107 5073 5065>,
			<6131 5542 5267 5112 5075 5067>,
			<6069 5526 5280 5117 5079 5069>,
			<6023 5506 5286 5125 5083 5072>,
			<6008 5486 5283 5139 5089 5076>,
			<5997 5465 5276 5152 5096 5081>,
			<5986 5446 5261 5151 5102 5086>,
			<5973 5429 5233 5139 5109 5094>,
			<5965 5417 5213 5125 5109 5095>,
			<5962 5409 5202 5104 5086 5077>,
			<5960 5404 5195 5088 5064 5059>,
			<5964 5398 5191 5086 5063 5058>,
			<5983 5391 5187 5086 5062 5058>,
			<6005 5389 5187 5086 5062 5058>,
			<6032 5390 5188 5087 5063 5058>,
			<6065 5391 5189 5088 5064 5059>,
			<6103 5394 5190 5091 5066 5060>,
			<6150 5398 5191 5095 5068 5062>,
			<6201 5404 5192 5098 5072 5065>,
			<6258 5417 5193 5101 5076 5070>,
			<6320 5432 5194 5102 5078 5072>,
			<6386 5448 5197 5101 5075 5068>,
			<6458 5468 5201 5100 5070 5063>,
			<6536 5492 5205 5096 5066 5061>,
			<6621 5521 5209 5089 5064 5059>,
			<6711 5554 5214 5088 5064 5059>,
			<6804 5589 5221 5090 5067 5062>,
			<6903 5630 5229 5091 5068 5064>,
			<7010 5679 5237 5091 5066 5062>,
			<7136 5727 5246 5093 5068 5065>,
			<7146 5746 5238 5087 5059 5053>,
			<7322 5840 5259 5089 5063 5059>,
			<7431 5900 5272 5094 5068 5066>,
			<7561 5978 5296 5098 5076 5078>,
			<7711 6078 5322 5110 5090 5092>,
			<7897 6217 5365 5123 5099 5096>,
			<8147 6414 5406 5120 5079 5070>,
			<8684 6743 5449 5102 5072 5069>,
			<11949 7613 5601 5113 5077 5073>,
			<31410 11935 6093 5127 5089 5086>,
			<31410 11935 6093 5127 5089 5086>,
			<31410 11935 6093 5127 5089 5086>;
	};

};
